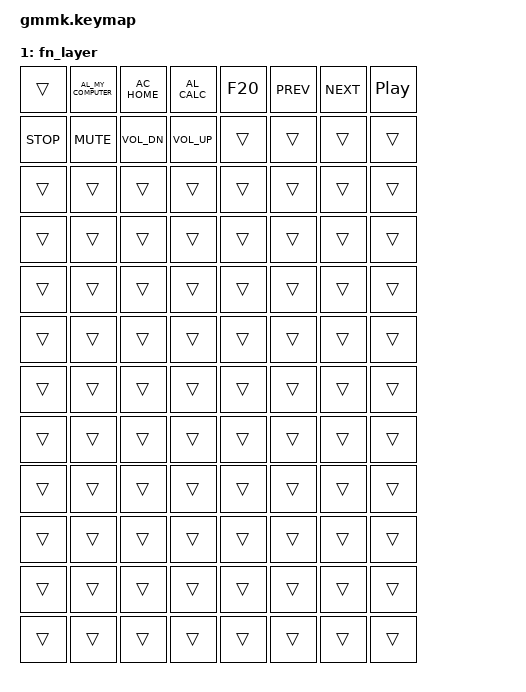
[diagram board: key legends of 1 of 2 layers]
#include <behaviors.dtsi>
#include <dt-bindings/zmk/keys.h>
#include <dt-bindings/zmk/bt.h>
#include <dt-bindings/zmk/ext_power.h>

/ {
    keymap {
        compatible = "zmk,keymap";

        default_layer {
            bindings = <
                /* Zeile 1 (16 Tasten) */
                &kp ESCAPE  &kp F1     &kp F2      &kp F3      &kp F4      &kp F5      &kp F6      &kp F7
                &kp F8      &kp F9     &kp F10     &kp F11     &kp F12     &kp PSCRN   &kp C_MUTE  &kp GRAVE

                /* Zeile 2 (16 Tasten) */
                &kp N1      &kp N2     &kp N3      &kp N4      &kp N5      &kp N6      &kp N7      &kp N8
                &kp N9      &kp N0     &kp MINUS   &kp EQUAL   &kp BSPC    &kp DEL     &kp TAB     &kp Q

                /* Zeile 3 (16 Tasten) */
                &kp W       &kp E      &kp R       &kp T       &kp Y       &kp U       &kp I       &kp O
                &kp P       &kp LBKT   &kp RBKT    &kp BSLH    &kp PG_UP   &kp CAPS    &kp A      &kp S

                /* Zeile 4 (16 Tasten) */
                &kp D       &kp F      &kp G       &kp H       &kp J       &kp K       &kp L       &kp SEMI
                &kp SQT     &kp ENTER  &kp PG_DN   &kp LSHFT   &kp Z       &kp X       &kp C      &kp V

                /* Zeile 5 (16 Tasten) */
                &kp B       &kp N      &kp M       &kp COMMA   &kp DOT     &kp FSLH    &kp RSHFT  &kp UP
                &kp END     &kp LCTRL  &kp LGUI    &kp LALT    &kp SPACE   &kp RALT    &mo 1      &kp RCTRL

                /* Zeile 6 (8 Tasten) */
                &kp LEFT    &kp DOWN   &kp RIGHT   &trans      &trans      &trans      &trans     &trans
            >;
            sensor-bindings = <&inc_vol &dec_vol>;

        };

        fn_layer {
            bindings = <
                /* Zeile 1 (16 Tasten) */
                &trans      &kp C_AL_MY_COMPUTER &kp C_AC_HOME &kp C_AL_CALC &kp F20   &kp C_PREV  &kp C_NEXT  &kp C_PP
                &kp C_STOP  &kp C_MUTE           &kp C_VOL_DN  &kp C_VOL_UP  &trans     &trans      &trans      &trans

                /* Zeile 2 (16 Tasten) */
                &trans      &trans     &trans      &trans      &trans      &trans      &trans      &trans
                &trans      &trans     &trans      &trans      &trans      &trans      &trans      &trans

                /* Zeile 3 (16 Tasten) */
                &trans      &trans     &trans      &trans      &trans      &trans      &trans      &trans
                &trans      &trans     &trans        &trans      &trans      &trans &trans      &trans

                /* Zeile 4 (16 Tasten) */
                &trans      &trans     &trans      &trans      &trans      &trans      &trans      &trans
                &trans      &trans     &trans      &trans        &trans      &trans      &trans      &trans

                /* Zeile 5 (16 Tasten) */
                &trans      &trans     &trans      &trans      &trans      &trans      &trans      &trans
                &trans      &trans     &trans      &trans      &trans      &trans      &trans      &trans

                /* Zeile 6 (8 Tasten) */
                &trans      &trans     &trans      &trans        &trans      &trans      &trans      &trans
                &trans      &trans     &trans      &trans      &trans        &trans      &trans      &trans
            >;
            sensor-bindings = <&inc_vol &dec_vol>;

        };
    };
};
